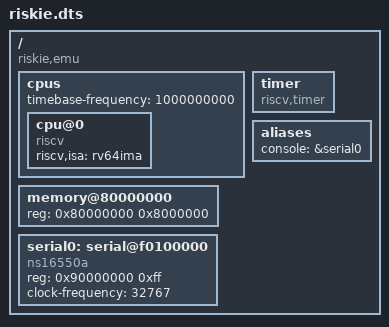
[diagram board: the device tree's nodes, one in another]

/dts-v1/;

/ {
	compatible = "riskie,emu";

	#address-cells = <1>;
	#size-cells = <1>;

	cpus {
		timebase-frequency = <1000000000>;

		cpu@0 {
			compatible = "riscv";
			riscv,isa = "rv64ima";
		};
	};

	memory@80000000 {
		device_type = "memory";
		reg = <0x80000000 0x8000000>;
	};

	serial0: serial@f0100000 {
		compatible = "ns16550a";
		reg = <0x90000000 0xff>;
		clock-frequency = <32767>;
	};

	timer {
		compatible = "riscv,timer";
	};

	aliases {
		console = &serial0;
	};
};
